# MKL28T7_CORE0 register map
Vendor: Freescale Semiconductor, Inc.; Series: Kinetis_L; File version: 1.6
CPU: CM0PLUS r0p0, little endian, no MPU, no FPU, VTOR, 2 interrupt priority bits
Registers are 32-bit, read-write, reset 0x0 unless marked. A register's access mark holds for its fields unless they carry their own. Offsets are from the block's base; [hi:lo] are bit positions; {n}, {i} and the like mark numbered series; 'fields as' and 'values as' point back to an identical list.

## PCC1
Base 0x400FA000
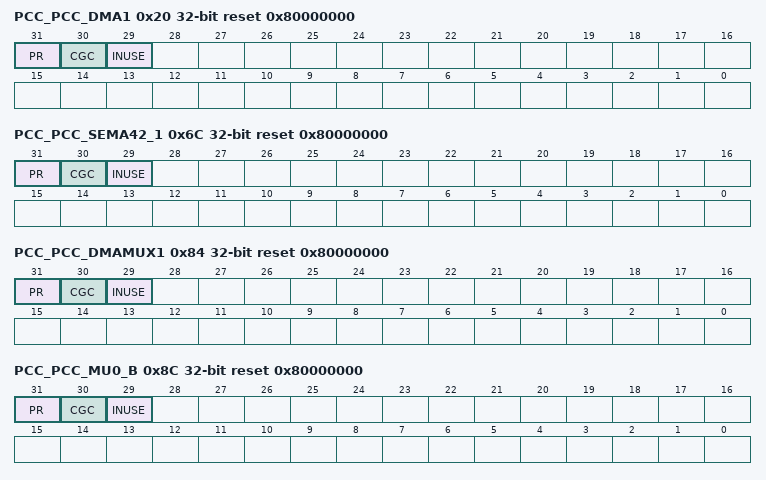
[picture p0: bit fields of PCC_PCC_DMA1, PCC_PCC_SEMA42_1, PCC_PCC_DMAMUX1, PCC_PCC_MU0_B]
0x20 PCC_PCC_DMA1 reset 0x80000000 — PCC_DMA1 Register
  [31] PR ro — Enable
    0=Peripheral is not present; 1=Peripheral is present
  [30] CGC — Clock Gate Control
    0=Clock disabled; 1=Clock enabled
  [29] INUSE ro — Clock Gate Control
    0=Another core is not using this peripheral; 1=Another core is using this peripheral. Software cannot modify the existing clocking configuration.
0x6C PCC_PCC_SEMA42_1 reset 0x80000000 — PCC_SEMA42_1 Register
  fields as PCC_PCC_DMA1
0x84 PCC_PCC_DMAMUX1 reset 0x80000000 — PCC_DMAMUX1 Register
  fields as PCC_PCC_DMA1
0x8C PCC_PCC_MU0_B reset 0x80000000 — PCC_MU0_B Register
  fields as PCC_PCC_DMA1
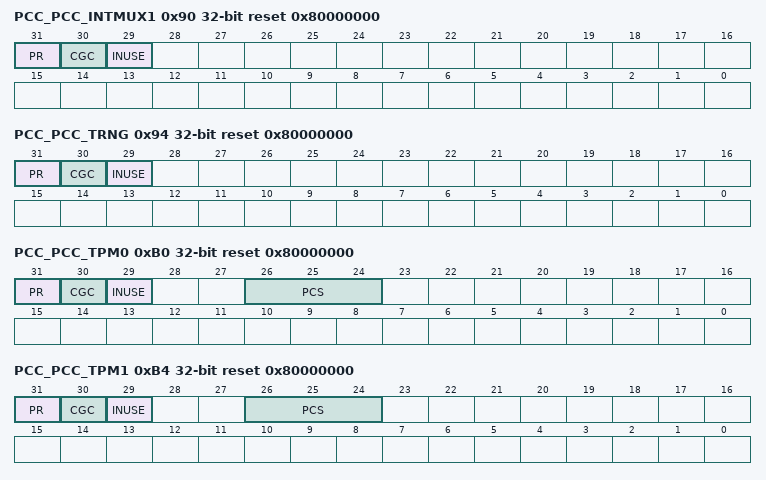
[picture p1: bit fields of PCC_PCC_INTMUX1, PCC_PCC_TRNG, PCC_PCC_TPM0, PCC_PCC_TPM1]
0x90 PCC_PCC_INTMUX1 reset 0x80000000 — PCC_INTMUX1 Register
  fields as PCC_PCC_DMA1
0x94 PCC_PCC_TRNG reset 0x80000000 — PCC_TRNG Register
  fields as PCC_PCC_DMA1
0xB0 PCC_PCC_TPM0 reset 0x80000000 — PCC_TPM0 Register
  [31] PR ro — Enable
    0=Peripheral is not present; 1=Peripheral is present
  [30] CGC — Clock Gate Control
    0=Clock disabled; 1=Clock enabled
  [29] INUSE ro — Clock Gate Control
    values as PCC_PCC_DMA1.INUSE
  [26:24] PCS — Peripheral Clock Source Select
    0=Clock is off (or test clock is enabled); 1=OSCCLK - System Oscillator Bus Clock(scg_sosc_slow_clk); 2=SCGIRCLK - Slow IRC Clock(scg_sirc_slow_clk), (maximum is 8MHz); 3=SCGFIRCLK - Fast IRC Clock(scg_firc_slow_clk), (maximum is 48MHz); 6=SCGPCLK System PLL clock (scg_spll_slow_clk)
0xB4 PCC_PCC_TPM1 reset 0x80000000 — PCC_TPM1 Register
  fields as PCC_PCC_TPM0
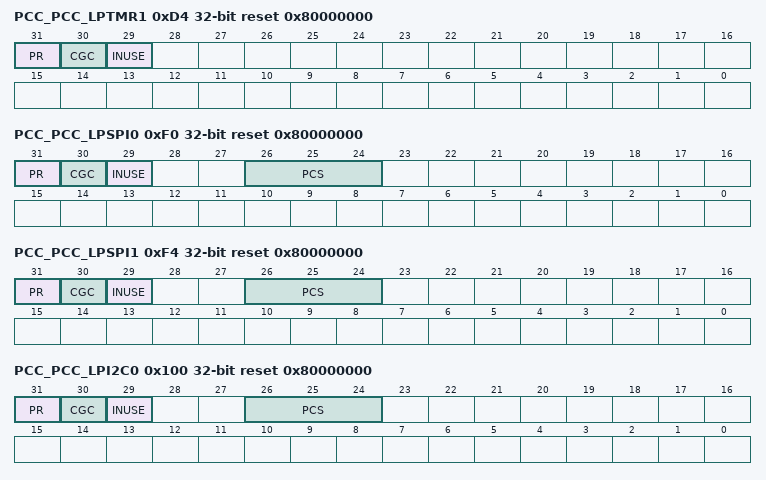
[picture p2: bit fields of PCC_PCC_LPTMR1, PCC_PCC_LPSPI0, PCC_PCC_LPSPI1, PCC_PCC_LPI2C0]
0xD4 PCC_PCC_LPTMR1 reset 0x80000000 — PCC_LPTMR1 Register
  fields as PCC_PCC_DMA1
0xF0 PCC_PCC_LPSPI0 reset 0x80000000 — PCC_LPSPI0 Register
  fields as PCC_PCC_TPM0
0xF4 PCC_PCC_LPSPI1 reset 0x80000000 — PCC_LPSPI1 Register
  fields as PCC_PCC_TPM0
0x100 PCC_PCC_LPI2C0 reset 0x80000000 — PCC_LPI2C0 Register
  fields as PCC_PCC_TPM0
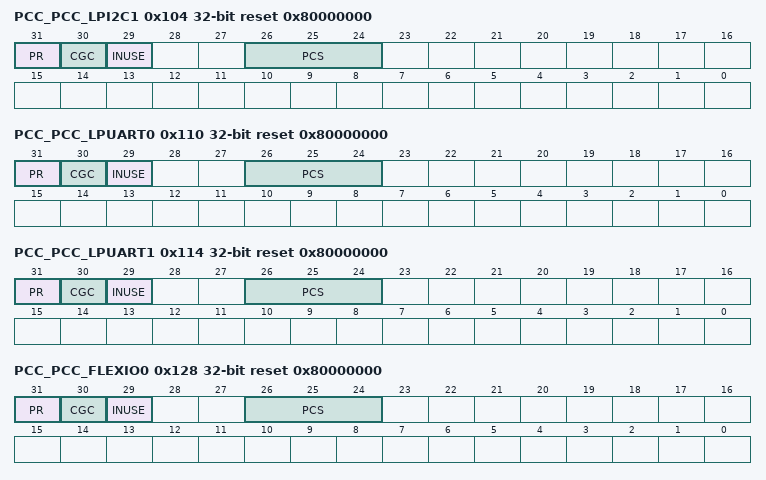
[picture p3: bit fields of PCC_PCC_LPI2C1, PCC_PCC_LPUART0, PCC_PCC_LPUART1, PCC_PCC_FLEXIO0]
0x104 PCC_PCC_LPI2C1 reset 0x80000000 — PCC_LPI2C1 Register
  fields as PCC_PCC_TPM0
0x110 PCC_PCC_LPUART0 reset 0x80000000 — PCC_LPUART0 Register
  fields as PCC_PCC_TPM0
0x114 PCC_PCC_LPUART1 reset 0x80000000 — PCC_LPUART1 Register
  fields as PCC_PCC_TPM0
0x128 PCC_PCC_FLEXIO0 reset 0x80000000 — PCC_FLEXIO0 Register
  fields as PCC_PCC_TPM0
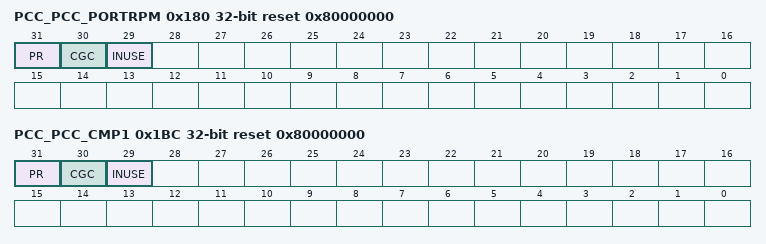
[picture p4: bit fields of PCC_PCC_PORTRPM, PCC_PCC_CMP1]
0x180 PCC_PCC_PORTRPM reset 0x80000000 — PCC_PORTRPM Register
  fields as PCC_PCC_DMA1
0x1BC PCC_PCC_CMP1 reset 0x80000000 — PCC_CMP1 Register
  fields as PCC_PCC_DMA1

## MTB0 — Micro Trace Buffer
Base 0xF0000000; register names take the prefix MTB0_
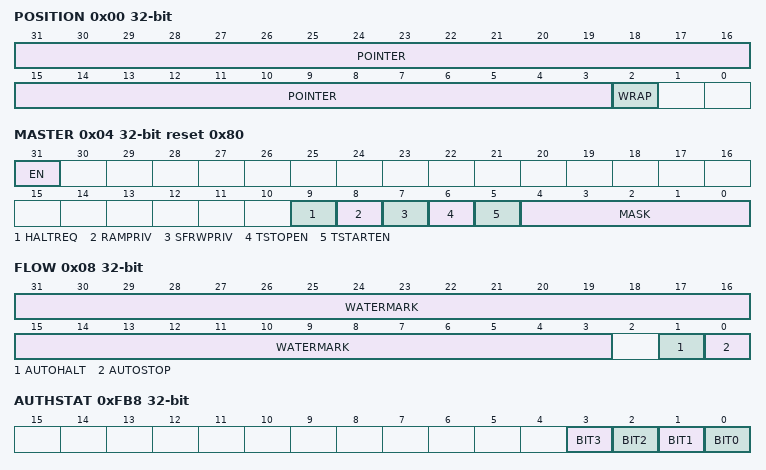
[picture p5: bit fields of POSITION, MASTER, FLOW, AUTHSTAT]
0x00 POSITION (reset mask 0x3) — MTB Position Register
  [31:3] POINTER — Trace Packet Address Pointer[28:0]
  [2] WRAP
0x04 MASTER reset 0x80 (reset mask 0xFFFFFFE0) — MTB Master Register
  [31] EN — Main Trace Enable
  [9] HALTREQ — Halt Request
  [8] RAMPRIV — RAM Privilege
  [7] SFRWPRIV — Special Function Register Write Privilege
  [6] TSTOPEN — Trace Stop Input Enable
  [5] TSTARTEN — Trace Start Input Enable
  [4:0] MASK
0x08 FLOW (reset mask 0x4) — MTB Flow Register
  [31:3] WATERMARK — WATERMARK[28:0]
  [1] AUTOHALT
  [0] AUTOSTOP
0x0C BASE ro reset not defined — MTB Base Register
  [31:0] BASEADDR
0xF00 MODECTRL ro — Integration Mode Control Register
0xFA0 TAGSET ro — Claim TAG Set Register
0xFA4 TAGCLEAR ro — Claim TAG Clear Register
0xFB0 LOCKACCESS ro
  [31:0] LOCKACCESS — Hardwired to 0x0000_0000
0xFB4 LOCKSTAT ro — Lock Status Register
0xFB8 AUTHSTAT ro — Authentication Status Register
  [3] BIT3
  [2] BIT2
  [1] BIT1
  [0] BIT0 — Connected to DBGEN.
0xFBC DEVICEARCH ro reset 0x47700A31 — Device Architecture Register
0xFC8 DEVICECFG ro — Device Configuration Register
0xFCC DEVICETYPID ro reset 0x31 — Device Type Identifier Register
0xFD0 PERIPHID{x} (x=4,5,6,7,0,1,2,3; step 0x4) ro reset not defined — Peripheral ID Register
  [31:0] PERIPHID
{0xFF0+4i} COMPID{i} (i=0..3) ro reset not defined — Component ID Register
  [31:0] COMPID — Component ID
